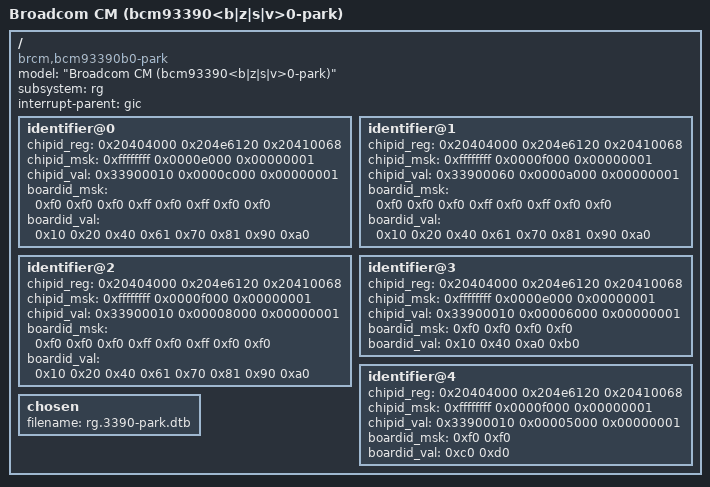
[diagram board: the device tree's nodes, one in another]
/dts-v1/;

/ {
	model = "Broadcom CM (bcm93390<b|z|s|v>0-park)";
	compatible = "brcm,bcm93390b0-park", "brcm,bcm93390z0-park", "brcm,bcm93390s0-park", "brcm,bcm93390v0-park",
		     "brcm,bcm3390b0-park", "brcm,bcm3390z0-park", "brcm,bcm3390s0-park", "brcm,bcm3390v0-park",
		     "brcm,bcm3390-park",
		     "brcm,bcm3390",
		     "brcm,brcmcm", "brcm,brcmstb";
	subsystem = "rg";
	#address-cells = <0x2>;
	#size-cells = <0x2>;
	interrupt-parent = <&gic>;

	identifier@0 {
			    /* chip id    mfg id     park       */
		chipid_reg = < 0x20404000 0x204e6120 0x20410068 >;
		chipid_msk = < 0xffffffff 0x0000e000 0x00000001 >;
		chipid_val = < 0x33900010 0x0000c000 0x00000001 >;
			     /* SV   MWVG SMWVG DCM  PHYDVT VCM  WVG  SDVT */
		boardid_msk = < 0xf0 0xf0 0xf0  0xff 0xf0   0xff 0xf0 0xf0 >;
		boardid_val = < 0x10 0x20 0x40  0x61 0x70   0x81 0x90 0xa0 >;
	};

	identifier@1 {
			    /* chip id    mfg id     park       */
		chipid_reg = < 0x20404000 0x204e6120 0x20410068 >;
		chipid_msk = < 0xffffffff 0x0000f000 0x00000001 >;
		chipid_val = < 0x33900060 0x0000a000 0x00000001 >;
			     /* SV   MWVG SMWVG DCM  PHYDVT VCM  WVG  SDVT */
		boardid_msk = < 0xf0 0xf0 0xf0  0xff 0xf0   0xff 0xf0 0xf0 >;
		boardid_val = < 0x10 0x20 0x40  0x61 0x70   0x81 0x90 0xa0 >;
	};

	identifier@2 {
			    /* chip id    mfg id     park       */
		chipid_reg = < 0x20404000 0x204e6120 0x20410068 >;
		chipid_msk = < 0xffffffff 0x0000f000 0x00000001 >;
		chipid_val = < 0x33900010 0x00008000 0x00000001 >;
			     /* SV   MWVG SMWVG DCM  PHYDVT VCM  WVG  SDVT */
		boardid_msk = < 0xf0 0xf0 0xf0  0xff 0xf0   0xff 0xf0 0xf0 >;
		boardid_val = < 0x10 0x20 0x40  0x61 0x70   0x81 0x90 0xa0 >;
	};

	identifier@3 {
			    /* chip id    mfg id     park       */
		chipid_reg = < 0x20404000 0x204e6120 0x20410068 >;
		chipid_msk = < 0xffffffff 0x0000e000 0x00000001 >;
		chipid_val = < 0x33900010 0x00006000 0x00000001 >;
			     /* SV   SMWVG SDVT SMWVG2 */
		boardid_msk = < 0xf0 0xf0  0xf0 0xf0 >;
		boardid_val = < 0x10 0x40  0xa0 0xb0 >;
	};

	identifier@4 {
			    /* chip id    mfg id     don't park */
		chipid_reg = < 0x20404000 0x204e6120 0x20410068 >;
		chipid_msk = < 0xffffffff 0x0000f000 0x00000001 >;
		chipid_val = < 0x33900010 0x00005000 0x00000001 >;
			     /* VSV  VVCM */
		boardid_msk = < 0xf0 0xf0 >;
		boardid_val = < 0xc0 0xd0 >;
	};
};

/include/ "rg.3390b0-bolt.dtsi"
/include/ "rg.3390-base.dtsi"
/include/ "rg.3390-park.dtsi"

/********************************************************************
 * any nodes that appear below are platform specific additions and
 * replacements.
 * The dtc will add or replace any properties in the nodes
 * below to the same nodes that appear in include files above.
 * If the property does not exist in the node above it will be added.
 * If the property does exist it will replace it.
 ********************************************************************/

/ {
	chosen {
		filename = "rg.3390-park.dtb";
	};
};
